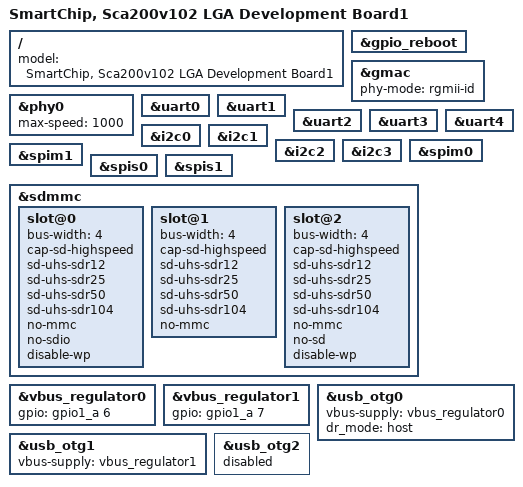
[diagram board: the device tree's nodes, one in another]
/*
 * Copyright 2015 SmartChip Co., Ltd.
 */

/dts-v1/;
#include <dt-bindings/gpio/gpio.h>
#include <dt-bindings/interrupt-controller/arm-gic.h>
#include <dt-bindings/sca200v100_common.h>
#include "smartchip-sca200v100-memory.dtsi"
#include "smartchip-sca200v100.dtsi"

/ {
	model = "SmartChip, Sca200v102 LGA Development Board1";
};

&gpio_reboot {
	status = "okay";
};

&gmac {
	phy-mode = "rgmii-id";
	status = "okay";
};
&phy0 {
	max-speed = <1000>;
};

&uart0 {
	status = "okay";
};
&uart1 {
	status = "okay";
};
&uart2 {
	status = "okay";
};
&uart3 {
	status = "okay";
};
&uart4 {
	status = "okay";
};

&i2c0 {
	status = "okay";
};

&i2c1 {
	status = "okay";
};

&i2c2 {
	status = "okay";
};

&i2c3 {
	status = "okay";
};

&spim0 {
	status = "okay";
};

&spim1 {
	status = "okay";
};

&spis0 {
	status = "okay";
};

&spis1 {
	status = "okay";
};

&sdmmc {
	status = "okay";

	slot@0 {
		/* tf card */
		bus-width = <4>;
		cap-sd-highspeed;
		sd-uhs-sdr12;
		sd-uhs-sdr25;
		sd-uhs-sdr50;
		sd-uhs-sdr104;

		no-mmc;
		no-sdio;
		disable-wp;

		status = "okay";
	};

	slot@1 {
		/* con */
		bus-width = <4>;
		cap-sd-highspeed;
		sd-uhs-sdr12;
		sd-uhs-sdr25;
		sd-uhs-sdr50;
		sd-uhs-sdr104;

		no-mmc;
		status = "okay";
	};

	slot@2 {
		/* wifi */
		bus-width = <4>;
		cap-sd-highspeed;
		sd-uhs-sdr12;
		sd-uhs-sdr25;
		sd-uhs-sdr50;
		sd-uhs-sdr104;

		no-mmc;
		no-sd;
		disable-wp;

		status = "okay";
	};

};

&vbus_regulator0 {
	gpio = <&gpio1_a 6 GPIO_ACTIVE_HIGH>;
};
&vbus_regulator1 {
	gpio = <&gpio1_a 7 GPIO_ACTIVE_HIGH>;
};
/delete-node/ &vbus_regulator2;

&usb_otg0 {
	vbus-supply = <&vbus_regulator0>;
	//dr_mode = "otg";
	dr_mode = "host";
	status = "okay";
};
&usb_otg1 {
	vbus-supply = <&vbus_regulator1>;
	status = "okay";
};
&usb_otg2 {
	status = "disabled";
};
